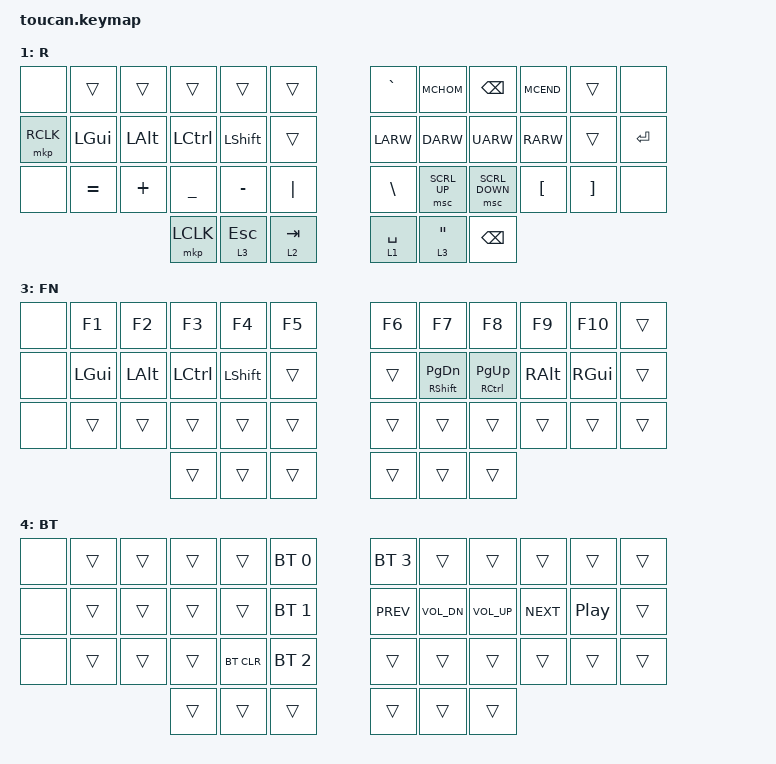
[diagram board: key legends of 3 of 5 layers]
#include <behaviors.dtsi>
#include <dt-bindings/zmk/keys.h>
#include <dt-bindings/zmk/bt.h>
#include <dt-bindings/zmk/pointing.h>
#include <dt-bindings/zmk/mouse.h>

#define HRML(k1,k2,k3,k4) &ht LGUI k1  &ht LALT k2  &ht LCTRL k3  &ht LSHFT k4
#define HRMR(k1,k2,k3,k4) &ht RSHFT k1  &ht RCTRL k2  &ht RALT k3  &ht RGUI k4
#define MCHOM LG(LARW)
#define MCEND LG(RARW)

/ {
    behaviors {
        ht: hold_tap {
            compatible = "zmk,behavior-hold-tap";
            #binding-cells = <2>;
            flavor = "tap-preferred";
            tapping-term-ms = <220>;
            quick-tap-ms = <150>;
            require-prior-idle-ms = <100>;
            bindings = <&kp>, <&kp>;
        };
    };

    keymap {
        compatible = "zmk,keymap";

        default_layer {
            display-name = "B";
            bindings = <
   &none    &kp Q      &kp W      &kp E      &kp R      &kp T          &kp Y      &kp U      &kp I      &kp O      &kp P      &none
 &mkp RCLK  HRML(A,        S,         D,         F)     &kp G          &kp H      HRMR(J,        K,         L,       SEMI)    &kp RET
   &none    &lt 4 Z    &kp X      &kp C      &kp V      &kp B          &kp N      &kp M      &kp COMMA  &kp DOT    &kp FSLH   &none 
                              &mkp LCLK  &lt 3 ESC  &lt 2 TAB          &lt 1 SPC  &lt 3 SQT &kp BSPC
            >;
        };

        first_layer {
            display-name = "R";
            bindings = <
   &none    &trans     &trans     &trans     &trans     &trans         &kp GRAVE  &kp MCHOM    &kp BSPC       &kp MCEND  &trans     &none
 &mkp RCLK  &kp LGUI   &kp LALT   &kp LCTRL  &kp LSHFT  &trans         &kp LARW   &kp DARW     &kp UARW       &kp RARW   &trans     &kp RET
   &none    &kp EQUAL  &kp PLUS   &kp UNDER  &kp MINUS  &kp PIPE       &kp BSLH   &msc SCRL_UP &msc SCRL_DOWN &kp LBKT   &kp RBKT   &none 
                                 &mkp LCLK   &lt 3 ESC  &lt 2 TAB      &lt 1 SPC  &lt 3 DQT &kp BSPC
            >;
        };

        second_layer {
            display-name = "L";
            bindings = <
   &none    &kp N1     &kp N2     &kp N3     &kp N4     &kp N5         &kp N6     &kp N7     &kp N8     &kp N9     &kp N0     &none
 &mkp RCLK  HRML(EXCL, AT,        HASH,      DLLR)      &kp PRCNT      &kp CARET  HRMR(AMPS, STAR,      LPAR,      RPAR)      &kp RET
   &none    &kp EQUAL  &kp PLUS   &kp UNDER  &kp MINUS  &kp PIPE       &kp BSLH   &kp LBRC   &kp RBRC   &kp LBKT   &kp RBKT   &none 
                                &mkp LCLK   &lt 3 ESC  &lt 2 TAB       &lt 1 SPC  &lt 3 DQT &kp BSPC
            >;
        };

        third_layer {
            display-name = "FN";
            bindings = <
   &none    &kp F1     &kp F2     &kp F3     &kp F4     &kp F5         &kp F6     &kp F7     &kp F8     &kp F9     &kp F10    &trans
   &none    &kp LGUI   &kp LALT   &kp LCTRL  &kp LSHFT  &trans         &trans     &mt RSHFT PG_DN  &mt RCTRL PG_UP  &kp RALT  &kp RGUI  &trans
   &none    &trans     &trans     &trans     &trans     &trans         &trans     &trans     &trans     &trans     &trans     &trans
                                  &trans     &trans     &trans         &trans     &trans     &trans
            >;
        };

        fourth_layer {
            display-name = "BT";
            bindings = <
   &none    &trans     &trans     &trans     &trans     &bt BT_SEL 0   &bt BT_SEL 3  &trans   &trans     &trans     &trans    &trans
   &none    &trans     &trans     &trans     &trans     &bt BT_SEL 1   &kp C_PREV &kp C_VOL_DN &kp C_VOL_UP &kp C_NEXT &kp C_PP &trans
   &none    &trans     &trans     &trans     &bt BT_CLR &bt BT_SEL 2   &trans     &trans      &trans     &trans     &trans    &trans
                                  &trans     &trans     &trans         &trans     &trans     &trans
            >;
        };
    };
};
